AUTOSAR XML (schema 4-2-2)
package /ETAS_BIP
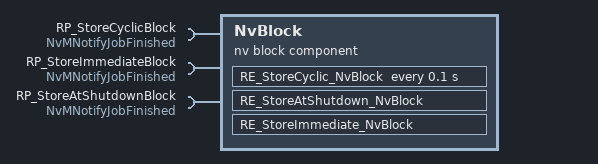
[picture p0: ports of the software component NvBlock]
  nv block sw component type NvBlock
    require port RP_StoreCyclicBlock: required-interface=NvMNotifyJobFinished
    require port RP_StoreImmediateBlock: required-interface=NvMNotifyJobFinished
    require port RP_StoreAtShutdownBlock: required-interface=NvMNotifyJobFinished
    provide/require port PRP_StoreCyclicBlock: provided-required-interface=SRI_CyclicNvBlock_ArrayU8_1024
    provide/require port PRP_StoreImmediateBlock: provided-required-interface=SRI_ImmediateNvBlock_ArrayU32_96
    provide/require port PRP_StoreAtShutdownBlock: provided-required-interface=SRI_ShutDownNvBlock_ArrayBoolean_96
    behavior IB_NvBlockDirtyFlag: data-type-mapping=DTMS_NvBlockDirtyFlag
      timing event TE_StoreCyclic_NvBlock: start-on-event=RE_StoreCyclic_NvBlock, period=0.1
      data received event DRE_NvBlock_StoreAtShutdownNvBlock: start-on-event=RE_StoreAtShutdown_NvBlock, data=PRP_StoreAtShutdownBlock.ShutDownNvBlock
      data received event DRE_NvBlock_StoreImmediateNvBlock: start-on-event=RE_StoreImmediate_NvBlock, data=PRP_StoreImmediateBlock.ImmediateNvBlock
      runnable RE_StoreAtShutdown_NvBlock
      runnable RE_StoreCyclic_NvBlock
      runnable RE_StoreImmediate_NvBlock
    nv block descriptor NvBlockDescriptor_StoreCyclicBlock: client-server-ports=role-based-port-assignment={port-prototype=RP_StoreCyclicBlock, role=NvMNotifyJobFinished}, nv-block-data-mapping{nv-ram-block-element=CyclicRamBlock, written-read-nv-data=PRP_StoreCyclicBlock.CyclicNvBlock}, support-dirty-flag=true, timing-event=TE_StoreCyclic_NvBlock
      nv block needs NvBlockNeeds_StoreCyclicBlock:
        calc-ram-block-crc=true
        check-static-block-id=false
        cyclic-writing-period=0.5
        n-rom-blocks=1
        readonly=false
        reliability=NO-PROTECTION
        resistant-to-changed-sw=true
        restore-at-start=true
        store-at-shutdown=false
        store-cyclic=true
        store-emergency=false
        store-immediate=false
        use-auto-validation-at-shut-down=false
        use-crc-comp-mechanism=false
        write-only-once=false
        write-verification=false
        writing-frequency=1
        writing-priority=MEDIUM
      ram block CyclicRamBlock: category=STRUCTURE, type=Type_ArrayU8_1024
      rom block CyclicRomBlock: category=STRUCTURE, type=Type_ArrayU8_1024, init-value=[66]
    nv block descriptor NvBlockDescriptor_StoreImmediateBlock: client-server-ports=role-based-port-assignment={port-prototype=RP_StoreImmediateBlock, role=NvMNotifyJobFinished}, nv-block-data-mapping{nv-ram-block-element=ImmediateRamBlock, written-read-nv-data=PRP_StoreImmediateBlock.ImmediateNvBlock}, support-dirty-flag=true
      nv block needs NvBlockNeeds_StoreImmediateBlock: calc-ram-block-crc=true, check-static-block-id=false, n-rom-blocks=1, readonly=false, reliability=NO-PROTECTION, resistant-to-changed-sw=true, restore-at-start=true, store-at-shutdown=false, store-cyclic=false, store-emergency=false, store-immediate=true, use-auto-validation-at-shut-down=false, use-crc-comp-mechanism=false, write-only-once=false, write-verification=false, writing-priority=MEDIUM
      ram block ImmediateRamBlock: category=STRUCTURE, type=Type_ArrayU32_96
      rom block ImmediateRomBlock: category=STRUCTURE, type=Type_ArrayU32_96, init-value=[50, 60, 70, 80, 90]
    nv block descriptor NvBlockDescriptor_StoreAtShutdownBlock: client-server-ports=role-based-port-assignment={port-prototype=RP_StoreAtShutdownBlock, role=NvMNotifyJobFinished}, nv-block-data-mapping{nv-ram-block-element=ShutdownRamBlock, written-read-nv-data=PRP_StoreAtShutdownBlock.ShutDownNvBlock}, support-dirty-flag=true
      nv block needs NvBlockNeeds_StoreAtShutdownBlock: calc-ram-block-crc=true, check-static-block-id=false, n-rom-blocks=1, readonly=false, reliability=NO-PROTECTION, resistant-to-changed-sw=true, restore-at-start=true, store-at-shutdown=true, store-cyclic=false, store-emergency=false, store-immediate=false, use-auto-validation-at-shut-down=false, use-crc-comp-mechanism=false, write-only-once=false, write-verification=false, writing-priority=MEDIUM
      ram block ShutdownRamBlock: category=STRUCTURE, type=Type_ArrayBoolean_96
      rom block ShutdownRomBlock: category=STRUCTURE, type=Type_ArrayBoolean_96, init-value=10 x 1
package /SwcImplementations
  swc implementation IMPL_rba_NvBlockDirtyFlag: programming-language=C, behavior=IB_NvBlockDirtyFlag
    code-descriptors:
      code Code: artifact-descriptors=autosar-engineering-object={short-label=AutosarEngineeringObject, category=SWSRC}
package /Units
  unit No_Unit
package /ApplicationDataTypes
  application array data type Type_ArrayU8_1024: category=ARRAY, sw-calibration-access=READ-ONLY
    element Element: category=VALUE, type=Type_U8, array-size-semantics=FIXED-SIZE, max-number-of-elements=1024
  app type Type_U8: category=VALUE, sw-calibration-access=READ-ONLY, compu-method=Identical
  app type Type_U16: category=VALUE, sw-calibration-access=READ-ONLY, compu-method=Identical
  application array data type Type_ArrayU32_96: category=ARRAY, sw-calibration-access=READ-ONLY
    element Element: category=VALUE, type=Type_U32, array-size-semantics=FIXED-SIZE, max-number-of-elements=96
  app type Type_U32: category=VALUE, sw-calibration-access=READ-ONLY, compu-method=Identical
  application record data type Type_Struct_U8U16U32: category=STRUCTURE, sw-calibration-access=READ-ONLY
    application record element U8: category=VALUE, type=Type_U8
    application record element U16: category=VALUE, type=Type_U16
    application record element U32: category=VALUE, type=Type_U32
  app type Type_float: category=VALUE, sw-calibration-access=READ-ONLY
  app type Type_boolean: category=VALUE, sw-calibration-access=READ-ONLY
  application array data type Type_ArrayBoolean_96: category=ARRAY, sw-calibration-access=READ-ONLY
    element Element: category=VALUE, type=Type_boolean, array-size-semantics=FIXED-SIZE, max-number-of-elements=96
  application record data type ImmediateRomBlock_VariableDataPrototype: category=STRUCTURE
    application record element Type_ArrayU32_96: category=ARRAY, type=Type_ArrayU32_96
  application record data type ShutdownRomBlock_VariableDataPrototype: category=STRUCTURE
    application record element Type_ArrayBoolean_96: category=ARRAY, type=Type_ArrayBoolean_96
  application record data type CyclicRomBlock_VariableDataPrototype: category=STRUCTURE
    application record element Type_ArrayU8_1024: category=ARRAY, type=Type_ArrayU8_1024
package /DataTypeMappingSets
  data type mapping set DTMS_NvBlockDirtyFlag
    data-type-maps:
      application-data-type=Type_U8, implementation-data-type=uint8
      application-data-type=Type_ArrayU8_1024, implementation-data-type=Type_ArrayU8_1024
      application-data-type=Type_U16, implementation-data-type=uint16
      application-data-type=Type_ArrayU32_96, implementation-data-type=Type_ArrayU32_96
      application-data-type=Type_ArrayBoolean_96, implementation-data-type=Type_ArrayBoolean_96
      application-data-type=Type_U32, implementation-data-type=uint32
      application-data-type=Type_Struct_U8U16U32, implementation-data-type=Type_Struct_U8U16U32
      application-data-type=Type_float, implementation-data-type=Type_float
      application-data-type=Type_boolean, implementation-data-type=Type_boolean
package /ImplementationDataTypes
  9 x impl type:
    Type_ArrayU8_1024: category=ARRAY
      element Element: array-size=1024, array-size-semantics=FIXED-SIZE, implementation-data-type=Type_U8
    Type_U8: implementation-data-type=uint8
    Type_U16: implementation-data-type=uint16
    Type_Struct_U8U16U32: category=STRUCTURE
      element U8: implementation-data-type=uint8
      element U16: implementation-data-type=uint16
      element U32: implementation-data-type=uint32
    Type_U32: implementation-data-type=uint32
    Type_ArrayU32_96: category=ARRAY
      element Element: array-size=96, array-size-semantics=FIXED-SIZE, implementation-data-type=uint32
    Type_float: implementation-data-type=float32
    Type_boolean: implementation-data-type=boolean
    Type_ArrayBoolean_96: category=ARRAY
      element Element: array-size=96, array-size-semantics=FIXED-SIZE, implementation-data-type=boolean
package /PortInterfaces
  nv data interface SRI_CyclicNvBlock_ArrayU8_1024
    nv-datas:
      data CyclicNvBlock: type=Type_ArrayU8_1024
  nv data interface SRI_ImmediateNvBlock_ArrayU32_96
    nv-datas:
      data ImmediateNvBlock: type=Type_ArrayU32_96
  nv data interface SRI_ShutDownNvBlock_ArrayBoolean_96
    nv-datas:
      data ShutDownNvBlock: type=Type_ArrayBoolean_96
package /NvM_Proxy_Interfaces
  client server interface CSI_NvBlock_SetRamBlockStatus
    operation NvBlock_SetRamBlockStatus
